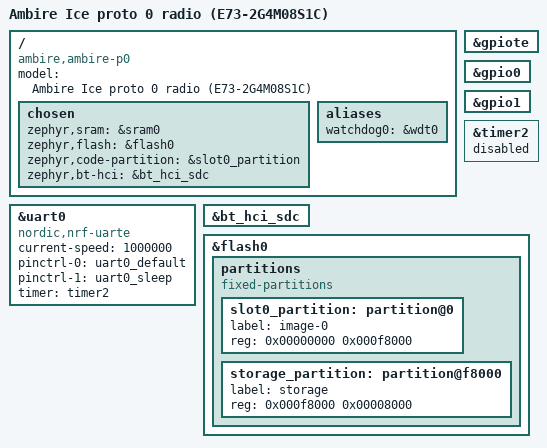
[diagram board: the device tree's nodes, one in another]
/*
 * Ambire Ice proto 0 radio: Ebyte E73-2G4M08S1C module (nRF52840, 1 MB flash,
 * 256 KB RAM, 32 MHz crystal on the module, no 32.768 kHz crystal).
 *
 * Its only link to the STM32 is a 2-wire UART (see the pinctrl file); its
 * power is switched by the STM32, which is its only reset. No buttons, no
 * LEDs. Flashed over the module's SWD pads as a plain image at 0x0 (no
 * MCUboot).
 */

/dts-v1/;
#include <nordic/nrf52840_qiaa.dtsi>
#include "ambire_p0-pinctrl.dtsi"

/ {
	model = "Ambire Ice proto 0 radio (E73-2G4M08S1C)";
	compatible = "ambire,ambire-p0";

	chosen {
		zephyr,sram = &sram0;
		zephyr,flash = &flash0;
		zephyr,code-partition = &slot0_partition;
		zephyr,bt-hci = &bt_hci_sdc;
	};

	aliases {
		watchdog0 = &wdt0;
	};
};

&gpiote {
	status = "okay";
};

&gpio0 {
	status = "okay";
};

&gpio1 {
	status = "okay";
};

/* Link to the STM32: 1 Mbaud 8N1, no flow control. Without flow control the
 * receiver counts bytes with a TIMER (through PPI) rather than in interrupts,
 * so a late interrupt (the Bluetooth controller runs at a higher priority)
 * cannot lose count. TIMER0 belongs to the radio scheduler (MPSL). */
&timer2 {
	status = "reserved";
};

&uart0 {
	compatible = "nordic,nrf-uarte";
	status = "okay";
	current-speed = <1000000>;
	pinctrl-0 = <&uart0_default>;
	pinctrl-1 = <&uart0_sleep>;
	pinctrl-names = "default", "sleep";
	timer = <&timer2>;
};

&bt_hci_sdc {
	status = "okay";
};

&flash0 {
	partitions {
		compatible = "fixed-partitions";
		#address-cells = <1>;
		#size-cells = <1>;

		/* No bootloader: the app image starts at 0x0. */
		slot0_partition: partition@0 {
			label = "image-0";
			reg = <0x00000000 0x000f8000>;
		};
		/* Bonds and settings (NVS). */
		storage_partition: partition@f8000 {
			label = "storage";
			reg = <0x000f8000 0x00008000>;
		};
	};
};
